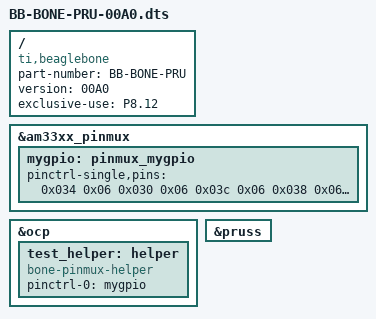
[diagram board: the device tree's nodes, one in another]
/*
* pru dts file BB-BONE-PRU-00A0.dts
*/
/dts-v1/;
/plugin/;
 

/ {
  compatible = "ti,beaglebone", "ti,beaglebone-black";
 
  /* identification */
  part-number = "BB-BONE-PRU";
  version = "00A0";
  exclusive-use =
	"P8.12";
 
  fragment@0 {
    target = <&am33xx_pinmux>;
    __overlay__ {
      mygpio: pinmux_mygpio{
        pinctrl-single,pins = <
		0x034 0x06 /* P8_11, SLEWCTRL_FAST | OUTPUT_PULLDOWN | MODE6 */
		0x030 0x06 /* P8_12, SLEWCTRL_FAST | OUTPUT_PULLDOWN | MODE6 */

		0x03c 0x06 /* P8_15, SLEWCTRL_FAST | OUTPUT_PULLDOWN | MODE6 */
		0x038 0x06 /* P8_16, SLEWCTRL_FAST | OUTPUT_PULLDOWN | MODE6 */

		0x0e0 0x26 /* P8_27, SLEWCTRL_FAST | INPUT_PULLDOWN | MODE6 */
		0x0e8 0x26 /* P8_28, SLEWCTRL_FAST | INPUT_PULLDOWN | MODE6 */
		0x0e4 0x26 /* P8_29, SLEWCTRL_FAST | INPUT_PULLDOWN | MODE6 */
		0x184 0x26 /* P9_24, SLEWCTRL_FAST | INPUT_PULLDOWN | MODE6 */
		0x180 0x26 /* P9_26, SLEWCTRL_FAST | INPUT_PULLDOWN | MODE6 */
		0x1a4 0x26 /* P9_27, SLEWCTRL_FAST | INPUT_PULLDOWN | MODE6 */
          >;
      };
    };
  };
 
  fragment@1 {
    target = <&ocp>;
    __overlay__ {
      test_helper: helper {
        compatible = "bone-pinmux-helper";
        pinctrl-names = "default";
        pinctrl-0 = <&mygpio>;
        status = "okay";
      };
    };
  };
 
  fragment@2{
  target = <&pruss>;
    __overlay__ {
      status = "okay";
    };
  };
};
